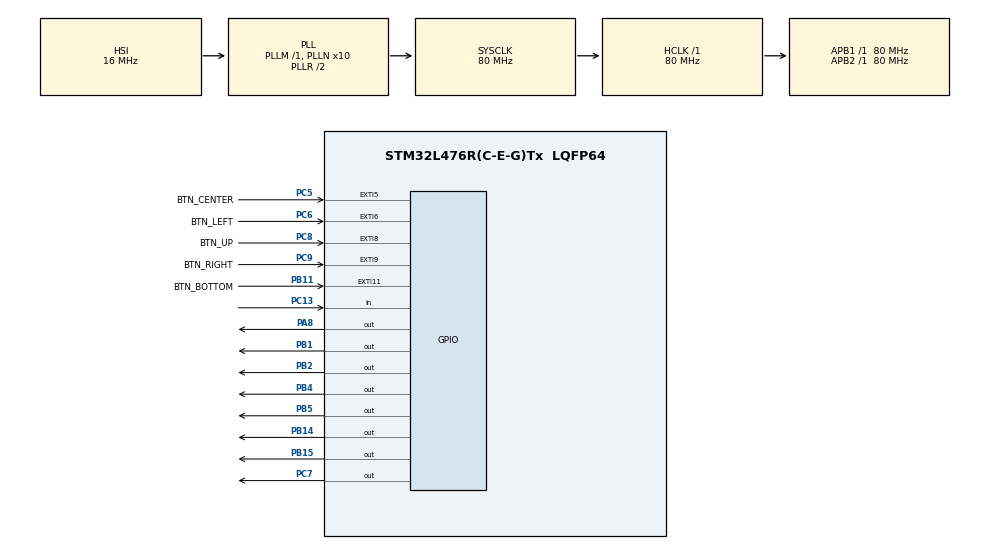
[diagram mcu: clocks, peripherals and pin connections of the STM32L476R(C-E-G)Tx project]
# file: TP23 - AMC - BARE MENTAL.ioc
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Mcu.Family=STM32L4
Mcu.Name=STM32L476R(C-E-G)Tx
Mcu.Package=LQFP64
NVIC.EXTI15_10_IRQn=true\:0\:0\:false\:true\:true\:2\:true\:true\:true
NVIC.EXTI9_5_IRQn=true\:0\:0\:false\:true\:true\:3\:true\:true\:true
NVIC.PriorityGroup=NVIC_PRIORITYGROUP_4
NVIC.TIM4_IRQn=true\:0\:0\:false\:true\:true\:1\:true\:true\:true
PA13\ (JTMS-SWDIO).GPIO_Label=TMS
PA13\ (JTMS-SWDIO).Mode=Serial_Wire
PA13\ (JTMS-SWDIO).Signal=SYS_JTMS-SWDIO
PA14\ (JTCK-SWCLK).GPIO_Label=TCK
PA14\ (JTCK-SWCLK).Mode=Serial_Wire
PA14\ (JTCK-SWCLK).Signal=SYS_JTCK-SWCLK
PA8.Signal=GPIO_Output
PB1.Signal=GPIO_Output
PB11.GPIO_Label=BTN_BOTTOM
PB11.GPIO_ModeDefaultEXTI=GPIO_MODE_IT_RISING_FALLING
PB11.Signal=GPXTI11
PB14.Signal=GPIO_Output
PB15.Signal=GPIO_Output
PB2.Signal=GPIO_Output
PB3\ (JTDO-TRACESWO).GPIO_Label=SWO
PB3\ (JTDO-TRACESWO).Signal=SYS_JTDO-SWO
PB4\ (NJTRST).Signal=GPIO_Output
PB5.Signal=GPIO_Output
PC13.Signal=GPIO_Input
PC14-OSC32_IN\ (PC14).Mode=LSE-External-Oscillator
PC14-OSC32_IN\ (PC14).Signal=RCC_OSC32_IN
PC15-OSC32_OUT\ (PC15).Mode=LSE-External-Oscillator
PC15-OSC32_OUT\ (PC15).Signal=RCC_OSC32_OUT
PC5.GPIO_Label=BTN_CENTER
PC5.GPIO_ModeDefaultEXTI=GPIO_MODE_IT_RISING_FALLING
PC5.Signal=GPXTI5
PC6.GPIO_Label=BTN_LEFT
PC6.GPIO_ModeDefaultEXTI=GPIO_MODE_IT_RISING_FALLING
PC6.Signal=GPXTI6
PC7.Signal=GPIO_Output
PC8.GPIO_Label=BTN_UP
PC8.GPIO_ModeDefaultEXTI=GPIO_MODE_IT_RISING_FALLING
PC8.Signal=GPXTI8
PC9.GPIO_Label=BTN_RIGHT
PC9.GPIO_ModeDefaultEXTI=GPIO_MODE_IT_RISING_FALLING
PC9.Signal=GPXTI9
PH0-OSC_IN\ (PH0).Signal=RCC_OSC_IN
PH1-OSC_OUT\ (PH1).Signal=RCC_OSC_OUT
ProjectManager.HeapSize=0x200
ProjectManager.StackSize=0x400
ProjectManager.TargetToolchain=STM32CubeIDE
RCC.ADCFreq_Value=64000000
RCC.AHBFreq_Value=80000000
RCC.APB1Freq_Value=80000000
RCC.APB1TimFreq_Value=80000000
RCC.APB2Freq_Value=80000000
RCC.APB2TimFreq_Value=80000000
RCC.CortexFreq_Value=80000000
RCC.HCLKFreq_Value=80000000
RCC.HSE_VALUE=8000000
RCC.HSI_VALUE=16000000
RCC.MSI_VALUE=4000000
RCC.PLLN=10
RCC.PLLSourceVirtual=RCC_PLLSOURCE_HSI
RCC.PREFETCH_ENABLE=1
RCC.SYSCLKFreq_VALUE=80000000
RCC.SYSCLKSource=RCC_SYSCLKSOURCE_PLLCLK
RCC.USBFreq_Value=64000000
RCC.VCOOutputFreq_Value=160000000
TIM4.AutoReloadPreload=TIM_AUTORELOAD_PRELOAD_DISABLE
TIM4.Period=4999
TIM4.Prescaler=79
VP_TIM4_VS_ClockSourceINT.Mode=Internal
board=NUCLEO-L476RG

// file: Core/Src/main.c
/* USER CODE BEGIN Header */
/**
  ******************************************************************************
  * @file           : main.c
  * @brief          : Main program body
  ******************************************************************************
  * @attention
  *
  * Copyright (c) 2025 STMicroelectronics.
  * All rights reserved.
  *
  * This software is licensed under terms that can be found in the LICENSE file
  * in the root directory of this software component.
  * If no LICENSE file comes with this software, it is provided AS-IS.
  *
  ******************************************************************************
  */
/* USER CODE END Header */
#include "main.h"

/* USER CODE BEGIN Includes */
#include <stdio.h>
#include "LED.h"
#include "utils.h"
#include "button.h"
#include "task.h"
/* USER CODE END Includes */

TIM_HandleTypeDef htim4;

void SystemClock_Config(void);
static void MX_GPIO_Init(void);
static void MX_TIM4_Init(void);
static void MX_NVIC_Init(void);

/* USER CODE BEGIN 0 */

/*
int __io_putchar(int ch){
HAL_UART_Transmit(&huart2, (uint8_t *)&ch, 1, HAL_MAX_DELAY);
return ch;}

int __io_getchar(void){
uint8_t ch = 0;
__HAL_UART_CLEAR_OREFLAG(&huart2);
HAL_UART_Receive(&huart2, (uint8_t *)&ch, 1, HAL_MAX_DELAY);
HAL_UART_Transmit(&huart2, (uint8_t *)&ch, 1, HAL_MAX_DELAY);
return ch;}
*/

/* USER CODE END 0 */

int main(void)
{

  /* MCU Configuration--------------------------------------------------------*/

  /* Reset of all peripherals, Initializes the Flash interface and the Systick. */
  HAL_Init();

  /* Configure the system clock */
  SystemClock_Config();

  /* Initialize all configured peripherals */
  MX_GPIO_Init();
  MX_TIM4_Init();

  /* Initialize interrupts */
  MX_NVIC_Init();

  /* Infinite loop */
  /* USER CODE BEGIN WHILE */

  TASK_Init();

  LED_Enable();
  LED_Configure();

  BUTTON_Enable();
  BUTTON_Config();

  //setup();

  while(1){//loop(); //HAL_Delay(1000);
  }
  /////ATTENTION J4AI ECRIT DES TRUCS BIZARRES DANS stm32l4xx_hal_gpio.c !!!!!!!

  while (1)
  {

    /* USER CODE END WHILE */

  }
}

void SystemClock_Config(void)
{
  RCC_OscInitTypeDef RCC_OscInitStruct = {0};
  RCC_ClkInitTypeDef RCC_ClkInitStruct = {0};

  /** Configure the main internal regulator output voltage
  */
  if (HAL_PWREx_ControlVoltageScaling(PWR_REGULATOR_VOLTAGE_SCALE1) != HAL_OK)
  {
    Error_Handler();
  }

  /** Initializes the RCC Oscillators according to the specified parameters
  * in the RCC_OscInitTypeDef structure.
  */
  RCC_OscInitStruct.OscillatorType = RCC_OSCILLATORTYPE_HSI;
  RCC_OscInitStruct.HSIState = RCC_HSI_ON;
  RCC_OscInitStruct.HSICalibrationValue = RCC_HSICALIBRATION_DEFAULT;
  RCC_OscInitStruct.PLL.PLLState = RCC_PLL_ON;
  RCC_OscInitStruct.PLL.PLLSource = RCC_PLLSOURCE_HSI;
  RCC_OscInitStruct.PLL.PLLM = 1;
  RCC_OscInitStruct.PLL.PLLN = 10;
  RCC_OscInitStruct.PLL.PLLP = RCC_PLLP_DIV7;
  RCC_OscInitStruct.PLL.PLLQ = RCC_PLLQ_DIV2;
  RCC_OscInitStruct.PLL.PLLR = RCC_PLLR_DIV2;
  if (HAL_RCC_OscConfig(&RCC_OscInitStruct) != HAL_OK)
  {
    Error_Handler();
  }

  /** Initializes the CPU, AHB and APB buses clocks
  */
  RCC_ClkInitStruct.ClockType = RCC_CLOCKTYPE_HCLK|RCC_CLOCKTYPE_SYSCLK
                              |RCC_CLOCKTYPE_PCLK1|RCC_CLOCKTYPE_PCLK2;
  RCC_ClkInitStruct.SYSCLKSource = RCC_SYSCLKSOURCE_PLLCLK;
  RCC_ClkInitStruct.AHBCLKDivider = RCC_SYSCLK_DIV1;
  RCC_ClkInitStruct.APB1CLKDivider = RCC_HCLK_DIV1;
  RCC_ClkInitStruct.APB2CLKDivider = RCC_HCLK_DIV1;

  if (HAL_RCC_ClockConfig(&RCC_ClkInitStruct, FLASH_LATENCY_4) != HAL_OK)
  {
    Error_Handler();
  }
}

/**
  * @brief NVIC Configuration.
  * @retval None
  */
static void MX_NVIC_Init(void)
{
  /* TIM4_IRQn interrupt configuration */
  HAL_NVIC_SetPriority(TIM4_IRQn, 0, 0);
  HAL_NVIC_EnableIRQ(TIM4_IRQn);
  /* EXTI15_10_IRQn interrupt configuration */
  HAL_NVIC_SetPriority(EXTI15_10_IRQn, 0, 0);
  HAL_NVIC_EnableIRQ(EXTI15_10_IRQn);
  /* EXTI9_5_IRQn interrupt configuration */
  HAL_NVIC_SetPriority(EXTI9_5_IRQn, 0, 0);
  HAL_NVIC_EnableIRQ(EXTI9_5_IRQn);
}

static void MX_TIM4_Init(void)
{

  TIM_ClockConfigTypeDef sClockSourceConfig = {0};
  TIM_MasterConfigTypeDef sMasterConfig = {0};

  htim4.Instance = TIM4;
  htim4.Init.Prescaler = 79;
  htim4.Init.CounterMode = TIM_COUNTERMODE_UP;
  htim4.Init.Period = 4999;
  htim4.Init.ClockDivision = TIM_CLOCKDIVISION_DIV1;
  htim4.Init.AutoReloadPreload = TIM_AUTORELOAD_PRELOAD_DISABLE;
  if (HAL_TIM_Base_Init(&htim4) != HAL_OK)
  {
    Error_Handler();
  }
  sClockSourceConfig.ClockSource = TIM_CLOCKSOURCE_INTERNAL;
  if (HAL_TIM_ConfigClockSource(&htim4, &sClockSourceConfig) != HAL_OK)
  {
    Error_Handler();
  }
  sMasterConfig.MasterOutputTrigger = TIM_TRGO_RESET;
  sMasterConfig.MasterSlaveMode = TIM_MASTERSLAVEMODE_DISABLE;
  if (HAL_TIMEx_MasterConfigSynchronization(&htim4, &sMasterConfig) != HAL_OK)
  {
    Error_Handler();
  }

}

static void MX_GPIO_Init(void)
{
  GPIO_InitTypeDef GPIO_InitStruct = {0};

  /* GPIO Ports Clock Enable */
  __HAL_RCC_GPIOC_CLK_ENABLE();
  __HAL_RCC_GPIOH_CLK_ENABLE();
  __HAL_RCC_GPIOB_CLK_ENABLE();
  __HAL_RCC_GPIOA_CLK_ENABLE();

  /*Configure GPIO pin Output Level */
  HAL_GPIO_WritePin(GPIOB, GPIO_PIN_1|GPIO_PIN_2|GPIO_PIN_14|GPIO_PIN_15
                          |GPIO_PIN_4|GPIO_PIN_5, GPIO_PIN_RESET);

  /*Configure GPIO pin Output Level */
  HAL_GPIO_WritePin(GPIOC, GPIO_PIN_7, GPIO_PIN_RESET);

  /*Configure GPIO pin Output Level */
  HAL_GPIO_WritePin(GPIOA, GPIO_PIN_8, GPIO_PIN_RESET);

  /*Configure GPIO pin : PC13 */
  GPIO_InitStruct.Pin = GPIO_PIN_13;
  GPIO_InitStruct.Mode = GPIO_MODE_INPUT;
  GPIO_InitStruct.Pull = GPIO_NOPULL;
  HAL_GPIO_Init(GPIOC, &GPIO_InitStruct);

  /*Configure GPIO pins : BTN_CENTER_Pin BTN_LEFT_Pin BTN_UP_Pin BTN_RIGHT_Pin */
  GPIO_InitStruct.Pin = BTN_CENTER_Pin|BTN_LEFT_Pin|BTN_UP_Pin|BTN_RIGHT_Pin;
  GPIO_InitStruct.Mode = GPIO_MODE_IT_RISING_FALLING;
  GPIO_InitStruct.Pull = GPIO_NOPULL;
  HAL_GPIO_Init(GPIOC, &GPIO_InitStruct);

  /*Configure GPIO pins : PB1 PB2 PB14 PB15
                           PB4 PB5 */
  GPIO_InitStruct.Pin = GPIO_PIN_1|GPIO_PIN_2|GPIO_PIN_14|GPIO_PIN_15
                          |GPIO_PIN_4|GPIO_PIN_5;
  GPIO_InitStruct.Mode = GPIO_MODE_OUTPUT_PP;
  GPIO_InitStruct.Pull = GPIO_NOPULL;
  GPIO_InitStruct.Speed = GPIO_SPEED_FREQ_LOW;
  HAL_GPIO_Init(GPIOB, &GPIO_InitStruct);

  /*Configure GPIO pin : BTN_BOTTOM_Pin */
  GPIO_InitStruct.Pin = BTN_BOTTOM_Pin;
  GPIO_InitStruct.Mode = GPIO_MODE_IT_RISING_FALLING;
  GPIO_InitStruct.Pull = GPIO_NOPULL;
  HAL_GPIO_Init(BTN_BOTTOM_GPIO_Port, &GPIO_InitStruct);

  /*Configure GPIO pin : PC7 */
  GPIO_InitStruct.Pin = GPIO_PIN_7;
  GPIO_InitStruct.Mode = GPIO_MODE_OUTPUT_PP;
  GPIO_InitStruct.Pull = GPIO_NOPULL;
  GPIO_InitStruct.Speed = GPIO_SPEED_FREQ_LOW;
  HAL_GPIO_Init(GPIOC, &GPIO_InitStruct);

  /*Configure GPIO pin : PA8 */
  GPIO_InitStruct.Pin = GPIO_PIN_8;
  GPIO_InitStruct.Mode = GPIO_MODE_OUTPUT_PP;
  GPIO_InitStruct.Pull = GPIO_NOPULL;
  GPIO_InitStruct.Speed = GPIO_SPEED_FREQ_LOW;
  HAL_GPIO_Init(GPIOA, &GPIO_InitStruct);

}

void Error_Handler(void)
{
  __disable_irq();
  while (1)
  {
  }
}
